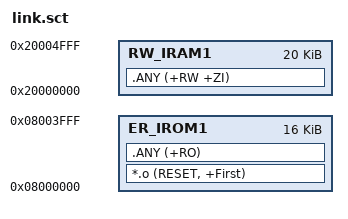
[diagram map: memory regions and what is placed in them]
; *************************************************************
; *** Bootloader Scatter File (ARMCC)
; *** Base: 0x08000000  Size: 16 KB (0x4000) — S0 only
; *************************************************************

; Bootloader 16KB (S0) + 20KB RAM
LR_IROM1 0x08000000 0x00004000  {
  ER_IROM1 0x08000000 0x00004000  {
   *.o (RESET, +First)
   .ANY (+RO)
  }
  RW_IRAM1 0x20000000 0x00005000  {
   .ANY (+RW +ZI)
  }
}
